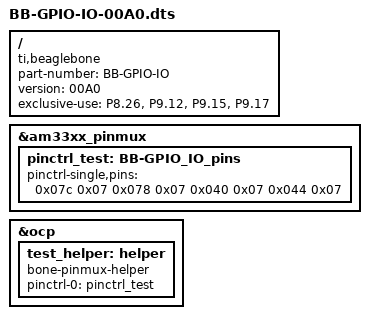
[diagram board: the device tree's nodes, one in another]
/*
* gpio initialisatie test
* versie 0.1
*/

/dts-v1/;
/plugin/;

/{
       compatible = "ti,beaglebone", "ti,beaglebone-black";
       part-number = "BB-GPIO-IO";
       version = "00A0";

	/* state the resources this cape uses */
	exclusive-use =
		/* the pin header uses */
		
		"P8.26",	/* GPIO1_29, buffer out enable */
		"P9.12",	/* GPIO1_28, display interrupt*/

		"P9.15",	/* GPIO1_16, protocol trans*/
		"P9.17";	/* GPIO1_17, Display Power Down */
		



       fragment@0 {
             target = <&am33xx_pinmux>;
            
             __overlay__ {
                  pinctrl_test: BB-GPIO_IO_pins {
			pinctrl-single,pins = <

				0x07c 0x07  /* P8_26 60 OUTPUT MODE7 - The LED Output */
				0x078 0x07  /* P9_12 60 OUTPUT MODE7 - The LED Output */
				
				0x040 0x07  /* P9_15 60 OUTPUT MODE7 - The LED Output */
				0x044 0x07  /* P9_23 60 OUTPUT MODE7 - The LED Output */
                       
                               /* OUTPUT  GPIO(mode7) 0x07 pulldown, 0x17 pullup, 0x?f no pullup/down */
			       /* INPUT   GPIO(mode7) 0x27 pulldown, 0x37 pullup, 0x?f no pullup/down */

			>;
		  };
             };
       };

       fragment@1 {
		target = <&ocp>;
		__overlay__ {
			test_helper: helper {
				compatible = "bone-pinmux-helper";
				pinctrl-names = "default";
				pinctrl-0 = <&pinctrl_test>;
				status = "okay";
			};
		};
	};
};
